# ESP32-S2 register map
Vendor: ESPRESSIF SYSTEMS (SHANGHAI) CO., LTD.; Series: ESP32 S-Series; File version: 20
CPU: Xtensa LX7 r0p0, little endian, no MPU, no FPU, 0 interrupt priority bits
Address unit: 32 bits
Registers are 32-bit, read-write, reset 0x0 unless marked. A register's access mark holds for its fields unless they carry their own. Offsets are from the block's base; [hi:lo] are bit positions; {n}, {i} and the like mark numbered series.

## UHCI0 — Universal Host Controller Interface 0
Base 0x3F414000
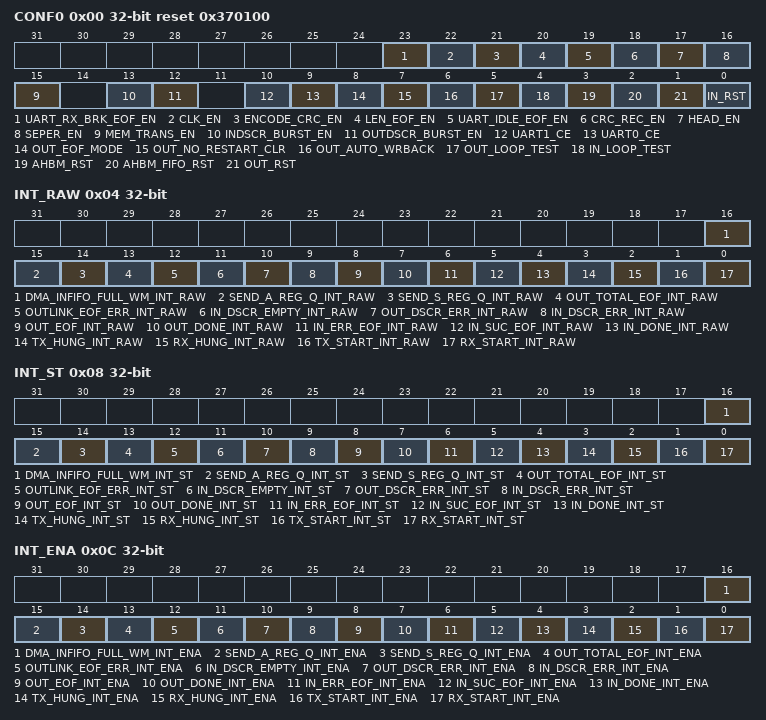
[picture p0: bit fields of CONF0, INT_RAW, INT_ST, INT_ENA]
0x00 CONF0 reset 0x370100 — UHCI configuration register
  [23] UART_RX_BRK_EOF_EN — If this bit is set to 1, UHCI stops receiving payload data when a NULL frame is received by UART.
  [22] CLK_EN — 1: Force clock on for registers. 0: Support clock only when application writes registers.
  [21] ENCODE_CRC_EN — Set this bit to enable data integrity checking by appending a 16 bit CCITT-CRC to the end of the payload.
  [20] LEN_EOF_EN — If this bit is set to 1, UHCI decoder stops receiving payload data when the number of received data bytes has reached the specified value. The value is payload length indicated by UCHI packet header when UHCI_HEAD_EN is 1 or the value is a configuration value when UHCI_HEAD_EN is 0. If this bit is set to 0, UHCI decoder stops receiving payload data upon receiving 0xC0.
  [19] UART_IDLE_EOF_EN — If this bit is set to 1, UHCI will end the payload receiving process when UART has been in idle state.
  [18] CRC_REC_EN — Set this bit to enable UHCI to receive the 16 bit CRC.
  [17] HEAD_EN — Set this bit to encode the data packet with a formatting header.
  [16] SEPER_EN — Set this bit to separate the data frame using a special character.
  [15] MEM_TRANS_EN — 1: UHCI transmitted data would be write back into DMA INFIFO.
  [13] INDSCR_BURST_EN — This register is used to specify DMA receive descriptor transfer mode. 1: burst mode. 0: byte mode.
  [12] OUTDSCR_BURST_EN — This register is used to specify DMA transmit descriptor transfer mode. 1: burst mode. 0: byte mode.
  [10] UART1_CE — Set this bit to link up UHCI and UART1.
  [9] UART0_CE — Set this bit to link up UHCI and UART0.
  [8] OUT_EOF_MODE — This register is used to specify the generation mode of UHCI_OUT_EOF_INT interrupt. 1: When DMA has popped all data from FIFO. 0: When AHB has pushed all data to FIFO.
  [7] OUT_NO_RESTART_CLR — Reserved.
  [6] OUT_AUTO_WRBACK — Set this bit to enable automatic outlink writeback when all the data in TX FIFO has been transmitted.
  [5] OUT_LOOP_TEST — Reserved.
  [4] IN_LOOP_TEST — Reserved.
  [3] AHBM_RST — Set this bit to reset AHB interface of DMA.
  [2] AHBM_FIFO_RST — Set this bit to reset AHB interface cmdFIFO of DMA.
  [1] OUT_RST — Set this bit to reset out DMA FSM.
  [0] IN_RST — Set this bit to reset in DMA FSM.
0x04 INT_RAW ro — Raw interrupt status
  [16] DMA_INFIFO_FULL_WM_INT_RAW — This is the interrupt raw bit for UHCI_DMA_INFIFO_FULL_WM_INT interrupt. The interrupt is triggered when the number of data bytes in DMA RX FIFO has reached the configured threshold value.
  [15] SEND_A_REG_Q_INT_RAW — This is the interrupt raw bit for UHCI_SEND_A_REG_Q_INT interrupt. The interrupt is triggered when DMA has sent out a short packet using always_send mode.
  [14] SEND_S_REG_Q_INT_RAW — This is the interrupt raw bit for UHCI_SEND_S_REG_Q_INT interrupt. The interrupt is triggered when DMA has sent out a short packet using single_send mode.
  [13] OUT_TOTAL_EOF_INT_RAW — This is the interrupt raw bit for UHCI_OUT_TOTAL_EOF_INT interrupt. The interrupt is triggered when all data in the last buffer address has been sent out.
  [12] OUTLINK_EOF_ERR_INT_RAW — This is the interrupt raw bit for UHCI_OUTLINK_EOF_ERR_INT interrupt. The interrupt is triggered when there are some errors in EOF in the transmit descriptor.
  [11] IN_DSCR_EMPTY_INT_RAW — This is the interrupt raw bit for UHCI_IN_DSCR_EMPTY_INT interrupt. The interrupt is triggered when there are not enough inlinks for DMA.
  [10] OUT_DSCR_ERR_INT_RAW — This is the interrupt raw bit for UHCI_OUT_DSCR_ERR_INT interrupt. The interrupt is triggered when there are some errors in the transmit descriptor.
  [9] IN_DSCR_ERR_INT_RAW — This is the interrupt raw bit for UHCI_IN_DSCR_ERR_INT interrupt. The interrupt is triggered when there are some errors in the receive descriptor.
  [8] OUT_EOF_INT_RAW — This is the interrupt raw bit for UHCI_OUT_EOF_INT interrupt. The interrupt is triggered when the current descriptor's EOF bit is 1.
  [7] OUT_DONE_INT_RAW — This is the interrupt raw bit for UHCI_OUT_DONE_INT interrupt. The interrupt is triggered when an transmit descriptor is completed.
  [6] IN_ERR_EOF_INT_RAW — This is the interrupt raw bit for UHCI_IN_ERR_EOF_INT interrupt. The interrupt is triggered when there are some errors in EOF in the receive descriptor.
  [5] IN_SUC_EOF_INT_RAW — This is the interrupt raw bit for UHCI_IN_SUC_EOF_INT interrupt. The interrupt is triggered when a data packet has been received successfully.
  [4] IN_DONE_INT_RAW — This is the interrupt raw bit for UHCI_IN_DONE_INT interrupt. The interrupt is triggered when an receive descriptor is completed.
  [3] TX_HUNG_INT_RAW — This is the interrupt raw bit for UHCI_TX_HUNG_INT interrupt. The interrupt is triggered when DMA takes more time to read data from RAM than the configured value.
  [2] RX_HUNG_INT_RAW — This is the interrupt raw bit for UHCI_RX_HUNG_INT interrupt. The interrupt is triggered when DMA takes more time to receive data than the configure value.
  [1] TX_START_INT_RAW — This is the interrupt raw bit for UHCI_TX_START_INT interrupt. The interrupt is triggered when DMA detects a separator.
  [0] RX_START_INT_RAW — This is the interrupt raw bit for UHCI_RX_START_INT interrupt. The interrupt is triggered when a separator has been sent.
0x08 INT_ST ro — Masked interrupt status
  [16] DMA_INFIFO_FULL_WM_INT_ST — This is the masked interrupt bit for UHCI_DMA_INFIFO_FULL_WM_INT INTERRUPT when UHCI_DMA_INFIFO_FULL_WM_INT_ENA is set to 1.
  [15] SEND_A_REG_Q_INT_ST — This is the masked interrupt bit for UHCI_SEND_A_REG_Q_INT interrupt when UHCI_SEND_A_REG_Q_INT_ENA is set to 1.
  [14] SEND_S_REG_Q_INT_ST — This is the masked interrupt bit for UHCI_SEND_S_REG_Q_INT interrupt when UHCI_SEND_S_REG_Q_INT_ENA is set to 1.
  [13] OUT_TOTAL_EOF_INT_ST — This is the masked interrupt bit for UHCI_OUT_TOTAL_EOF_INT interrupt when UHCI_OUT_TOTAL_EOF_INT_ENA is set to 1.
  [12] OUTLINK_EOF_ERR_INT_ST — This is the masked interrupt bit for UHCI_OUTLINK_EOF_ERR_INT interrupt when UHCI_OUTLINK_EOF_ERR_INT_ENA is set to 1.
  [11] IN_DSCR_EMPTY_INT_ST — This is the masked interrupt bit for UHCI_IN_DSCR_EMPTY_INT interrupt when UHCI_IN_DSCR_EMPTY_INT_ENA is set to 1.
  [10] OUT_DSCR_ERR_INT_ST — This is the masked interrupt bit for UHCI_OUT_DSCR_ERR_INT interrupt when UHCI_OUT_DSCR_ERR_INT_ENA is set to 1.
  [9] IN_DSCR_ERR_INT_ST — This is the masked interrupt bit for UHCI_IN_DSCR_ERR_INT interrupt when UHCI_IN_DSCR_ERR_INT is set to 1.
  [8] OUT_EOF_INT_ST — This is the masked interrupt bit for UHCI_OUT_EOF_INT interrupt when UHCI_OUT_EOF_INT_ENA is set to 1.
  [7] OUT_DONE_INT_ST — This is the masked interrupt bit for UHCI_OUT_DONE_INT interrupt when UHCI_OUT_DONE_INT_ENA is set to 1.
  [6] IN_ERR_EOF_INT_ST — This is the masked interrupt bit for UHCI_IN_ERR_EOF_INT interrupt when UHCI_IN_ERR_EOF_INT_ENA is set to 1.
  [5] IN_SUC_EOF_INT_ST — This is the masked interrupt bit for UHCI_IN_SUC_EOF_INT interrupt when UHCI_IN_SUC_EOF_INT_ENA is set to 1.
  [4] IN_DONE_INT_ST — This is the masked interrupt bit for UHCI_IN_DONE_INT interrupt when UHCI_IN_DONE_INT_ENA is set to 1.
  [3] TX_HUNG_INT_ST — This is the masked interrupt bit for UHCI_TX_HUNG_INT interrupt when UHCI_TX_HUNG_INT_ENA is set to 1.
  [2] RX_HUNG_INT_ST — This is the masked interrupt bit for UHCI_RX_HUNG_INT interrupt when UHCI_RX_HUNG_INT_ENA is set to 1.
  [1] TX_START_INT_ST — This is the masked interrupt bit for UHCI_TX_START_INT interrupt when UHCI_TX_START_INT_ENA is set to 1.
  [0] RX_START_INT_ST — This is the masked interrupt bit for UHCI_RX_START_INT interrupt when UHCI_RX_START_INT_ENA is set to 1.
0x0C INT_ENA — Interrupt enable bits
  [16] DMA_INFIFO_FULL_WM_INT_ENA — This is the interrupt enable bit for UHCI_DMA_INFIFO_FULL_WM_INT interrupt.
  [15] SEND_A_REG_Q_INT_ENA — This is the interrupt enable bit for UHCI_SEND_A_REG_Q_INT interrupt.
  [14] SEND_S_REG_Q_INT_ENA — This is the interrupt enable bit for UHCI_SEND_S_REG_Q_INT interrupt.
  [13] OUT_TOTAL_EOF_INT_ENA — This is the interrupt enable bit for UHCI_OUT_TOTAL_EOF_INT interrupt.
  [12] OUTLINK_EOF_ERR_INT_ENA — This is the interrupt enable bit for UHCI_OUTLINK_EOF_ERR_INT interrupt.
  [11] IN_DSCR_EMPTY_INT_ENA — This is the interrupt enable bit for UHCI_IN_DSCR_EMPTY_INT interrupt.
  [10] OUT_DSCR_ERR_INT_ENA — This is the interrupt enable bit for UHCI_OUT_DSCR_ERR_INT interrupt.
  [9] IN_DSCR_ERR_INT_ENA — This is the interrupt enable bit for UHCI_IN_DSCR_ERR_INT interrupt.
  [8] OUT_EOF_INT_ENA — This is the interrupt enable bit for UHCI_OUT_EOF_INT interrupt.
  [7] OUT_DONE_INT_ENA — This is the interrupt enable bit for UHCI_OUT_DONE_INT interrupt.
  [6] IN_ERR_EOF_INT_ENA — This is the interrupt enable bit for UHCI_IN_ERR_EOF_INT interrupt.
  [5] IN_SUC_EOF_INT_ENA — This is the interrupt enable bit for UHCI_IN_SUC_EOF_INT interrupt.
  [4] IN_DONE_INT_ENA — This is the interrupt enable bit for UHCI_IN_DONE_INT interrupt.
  [3] TX_HUNG_INT_ENA — This is the interrupt enable bit for UHCI_TX_HUNG_INT interrupt.
  [2] RX_HUNG_INT_ENA — This is the interrupt enable bit for UHCI_RX_HUNG_INT interrupt.
  [1] TX_START_INT_ENA — This is the interrupt enable bit for UHCI_TX_START_INT interrupt.
  [0] RX_START_INT_ENA — This is the interrupt enable bit for UHCI_RX_START_INT interrupt.
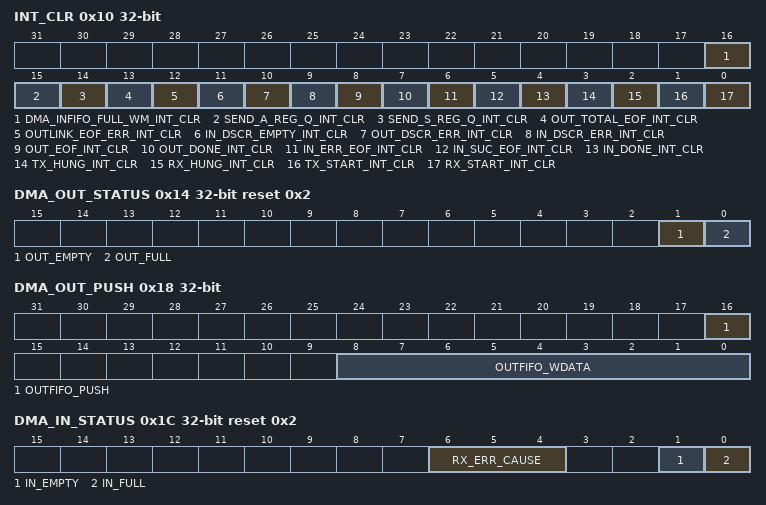
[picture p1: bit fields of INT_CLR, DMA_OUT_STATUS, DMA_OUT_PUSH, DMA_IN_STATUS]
0x10 INT_CLR wo — Interrupt clear bits
  [16] DMA_INFIFO_FULL_WM_INT_CLR — Set this bit to clear UHCI_DMA_INFIFO_FULL_WM_INT interrupt.
  [15] SEND_A_REG_Q_INT_CLR — Set this bit to clear UHCI_SEND_A_REG_Q_INT interrupt.
  [14] SEND_S_REG_Q_INT_CLR — Set this bit to clear UHCI_SEND_S_REG_Q_INT interrupt.
  [13] OUT_TOTAL_EOF_INT_CLR — Set this bit to clear UHCI_OUT_TOTAL_EOF_INT interrupt.
  [12] OUTLINK_EOF_ERR_INT_CLR — Set this bit to clear UHCI_OUTLINK_EOF_ERR_INT interrupt.
  [11] IN_DSCR_EMPTY_INT_CLR — Set this bit to clear UHCI_IN_DSCR_EMPTY_INT interrupt.
  [10] OUT_DSCR_ERR_INT_CLR — Set this bit to clear UHCI_OUT_DSCR_ERR_INT interrupt.
  [9] IN_DSCR_ERR_INT_CLR — Set this bit to clear UHCI_IN_DSCR_ERR_INT interrupt.
  [8] OUT_EOF_INT_CLR — Set this bit to clear UHCI_OUT_EOF_INT interrupt.
  [7] OUT_DONE_INT_CLR — Set this bit to clear UHCI_OUT_DONE_INT interrupt.
  [6] IN_ERR_EOF_INT_CLR — Set this bit to clear UHCI_IN_ERR_EOF_INT interrupt.
  [5] IN_SUC_EOF_INT_CLR — Set this bit to clear UHCI_IN_SUC_EOF_INT interrupt.
  [4] IN_DONE_INT_CLR — Set this bit to clear UHCI_IN_DONE_INT interrupt.
  [3] TX_HUNG_INT_CLR — Set this bit to clear UHCI_TX_HUNG_INT interrupt.
  [2] RX_HUNG_INT_CLR — Set this bit to clear UHCI_RX_HUNG_INT interrupt.
  [1] TX_START_INT_CLR — Set this bit to clear UHCI_TX_START_INT interrupt.
  [0] RX_START_INT_CLR — Set this bit to clear UHCI_RX_START_INT interrupt.
0x14 DMA_OUT_STATUS ro reset 0x2 — DMA data-output status register
  [1] OUT_EMPTY — 1: DMA TX FIFO is empty.
  [0] OUT_FULL — 1: DMA TX FIFO is full.
0x18 DMA_OUT_PUSH — Push control register of TX FIFO
  [16] OUTFIFO_PUSH — Set this bit to push data into TX FIFO.
  [8:0] OUTFIFO_WDATA — This is the data that need to be pushed into TX FIFO.
0x1C DMA_IN_STATUS ro reset 0x2 — UHCI data-input status register
  [6:4] RX_ERR_CAUSE — This register indicates the error type when DMA has received a packet with error. 3'b001: Checksum error in the HCI packet; 3'b010: Sequence number error in the HCI packet; 3'b011: CRC bit error in the HCI packet; 3'b100: 0xC0 is found but the received HCI packet is not end; 3'b101: 0xC0 is not found when the HCI packet has been received; 3'b110: CRC check error.
  [1] IN_EMPTY — Data-input FIFO empty signal.
  [0] IN_FULL — Data-input FIFO full signal.
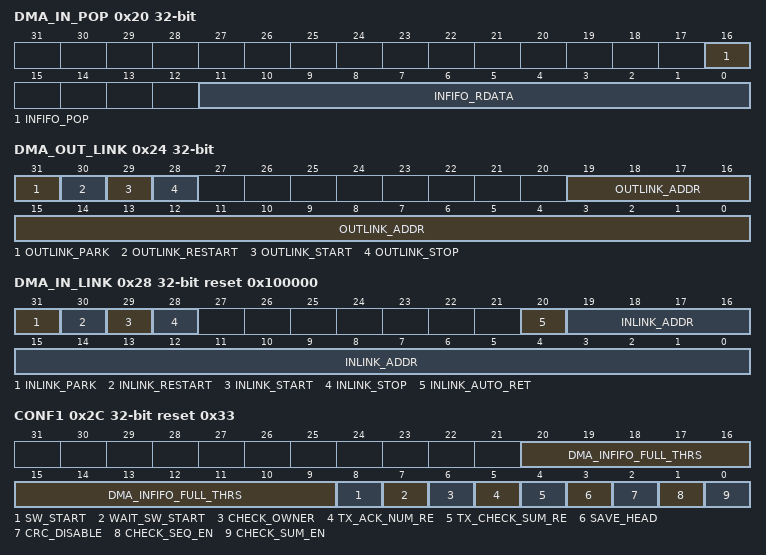
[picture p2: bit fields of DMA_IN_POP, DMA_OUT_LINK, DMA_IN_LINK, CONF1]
0x20 DMA_IN_POP access per field — Pop control register of RX FIFO
  [16] INFIFO_POP rw — Set this bit to pop data from RX FIFO.
  [11:0] INFIFO_RDATA ro — This register stores the data popping from RX FIFO.
0x24 DMA_OUT_LINK access per field — Link descriptor address and control
  [31] OUTLINK_PARK ro — 1: the transmit descriptor's FSM is in idle state. 0: the transmit descriptor's FSM is working.
  [30] OUTLINK_RESTART rw — Set this bit to restart the transmit descriptor from the last address.
  [29] OUTLINK_START rw — Set this bit to start a new transmit descriptor.
  [28] OUTLINK_STOP rw — Set this bit to stop dealing with the transmit descriptor.
  [19:0] OUTLINK_ADDR rw — This register is used to specify the least significant 20 bits of the first transmit descriptor's address.
0x28 DMA_IN_LINK access per field reset 0x100000 — Link descriptor address and control
  [31] INLINK_PARK ro — 1: the receive descriptor's FSM is in idle state. 0: the receive descriptor's FSM is working.
  [30] INLINK_RESTART rw — Set this bit to restart new receive descriptors.
  [29] INLINK_START rw — Set this bit to start dealing with the receive descriptors.
  [28] INLINK_STOP rw — Set this bit to stop dealing with the receive descriptors.
  [20] INLINK_AUTO_RET rw — This is the enable bit to return to current receive descriptor's address, when there are some errors in current packet.
  [19:0] INLINK_ADDR rw — This register is used to specify the least significant 20 bits of the first receive descriptor's address.
0x2C CONF1 reset 0x33 — UHCI configuration register
  [20:9] DMA_INFIFO_FULL_THRS — This field is used to generate the UHCI_DMA_INFIFO_FULL_WM_INT interrupt when the counter value of DMA RX FIFO exceeds the value of the register.
  [8] SW_START — If current UHCI_ENCODE_STATE is ST_SW_WAIT, the UHCI will start to send data packet out when this bit is set to 1.
  [7] WAIT_SW_START — The UHCI encoder will jump to ST_SW_WAIT status if this register is set to 1.
  [6] CHECK_OWNER — 1: Check the link list descriptor when link list owner is DMA controller; 0: Always check link list descriptor.
  [5] TX_ACK_NUM_RE — Set this bit to encode the data packet with an acknowledgement when a reliable packet is to be transmit.
  [4] TX_CHECK_SUM_RE — Set this bit to encode the data packet with a checksum.
  [3] SAVE_HEAD — Set this bit to save the packet header when UHCI receives a data packet.
  [2] CRC_DISABLE — Set this bit to support CRC calculation. Data Integrity check present bit in UHCI packet frame should be 1.
  [1] CHECK_SEQ_EN — This is the enable bit to check sequence number when UHCI receives a data packet.
  [0] CHECK_SUM_EN — This is the enable bit to check header checksum when UHCI receives a data packet.
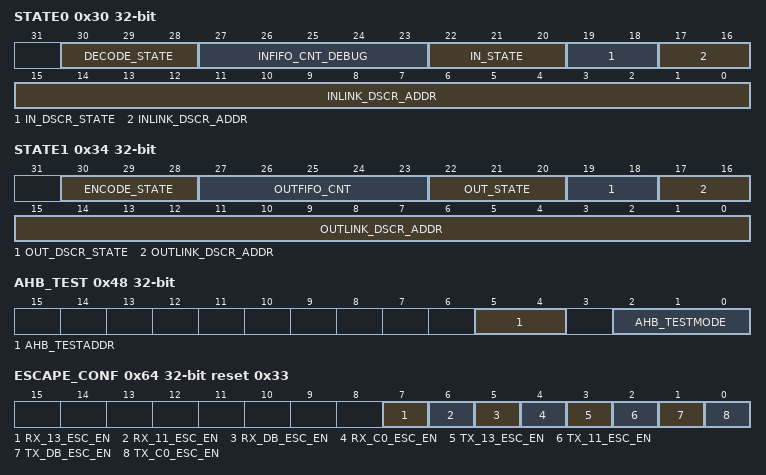
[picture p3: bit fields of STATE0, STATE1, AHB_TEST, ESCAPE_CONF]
0x30 STATE0 ro — UHCI decoder status register
  [30:28] DECODE_STATE — UHCI decoder status.
  [27:23] INFIFO_CNT_DEBUG — This register stores the number of data bytes in RX FIFO.
  [22:20] IN_STATE — Reserved.
  [19:18] IN_DSCR_STATE — Reserved.
  [17:0] INLINK_DSCR_ADDR — This register stores the current receive descriptor's address.
0x34 STATE1 ro — UHCI encoder status register
  [30:28] ENCODE_STATE — UHCI encoder status.
  [27:23] OUTFIFO_CNT — This register stores the number of data bytes in TX FIFO.
  [22:20] OUT_STATE — Reserved.
  [19:18] OUT_DSCR_STATE — Reserved.
  [17:0] OUTLINK_DSCR_ADDR — This register stores the current transmit descriptor's address.
0x38 DMA_OUT_EOF_DES_ADDR ro — Outlink descriptor address when EOF occurs
  [31:0] OUT_EOF_DES_ADDR — This register stores the address of the transmit descriptor when the EOF bit in this descriptor is 1.
0x3C DMA_IN_SUC_EOF_DES_ADDR ro — Inlink descriptor address when EOF occurs
  [31:0] IN_SUC_EOF_DES_ADDR — This register stores the address of the receive descriptor when received successful EOF.
0x40 DMA_IN_ERR_EOF_DES_ADDR ro — Inlink descriptor address when errors occur
  [31:0] IN_ERR_EOF_DES_ADDR — This register stores the address of the receive descriptor when there are some errors in this descriptor.
0x44 DMA_OUT_EOF_BFR_DES_ADDR ro — Outlink descriptor address before the last transmit descriptor
  [31:0] OUT_EOF_BFR_DES_ADDR — This register stores the address of the transmit descriptor before the last transmit descriptor.
0x48 AHB_TEST
  [5:4] AHB_TESTADDR — Reserved.
  [2:0] AHB_TESTMODE — Reserved.
0x4C DMA_IN_DSCR ro — The third word of the next receive descriptor
  [31:0] INLINK_DSCR — This register stores the third word of the next receive descriptor.
0x50 DMA_IN_DSCR_BF0 ro — The third word of current receive descriptor
  [31:0] INLINK_DSCR_BF0 — This register stores the third word of the current receive descriptor.
0x58 DMA_OUT_DSCR ro — The third word of the next transmit descriptor
  [31:0] OUTLINK_DSCR — This register stores the third word of the next transmit descriptor.
0x5C DMA_OUT_DSCR_BF0 ro — The third word of current transmit descriptor
  [31:0] OUTLINK_DSCR_BF0 — This register stores the third word of the current transmit descriptor.
0x64 ESCAPE_CONF reset 0x33 — Escape character configuration
  [7] RX_13_ESC_EN — Set this bit to replace flow control character 0x13 by special characters when DMA sends data.
  [6] RX_11_ESC_EN — Set this bit to replace flow control character 0x11 by special characters when DMA sends data.
  [5] RX_DB_ESC_EN — Set this bit to replace 0xDB by special characters when DMA sends data.
  [4] RX_C0_ESC_EN — Set this bit to replace 0xC0 by special characters when DMA sends data.
  [3] TX_13_ESC_EN — Set this bit to decode flow control character 0x13 when DMA receives data.
  [2] TX_11_ESC_EN — Set this bit to decode flow control character 0x11 when DMA receives data.
  [1] TX_DB_ESC_EN — Set this bit to decode character 0xDB when DMA receives data.
  [0] TX_C0_ESC_EN — Set this bit to decode character 0xC0 when DMA receives data.
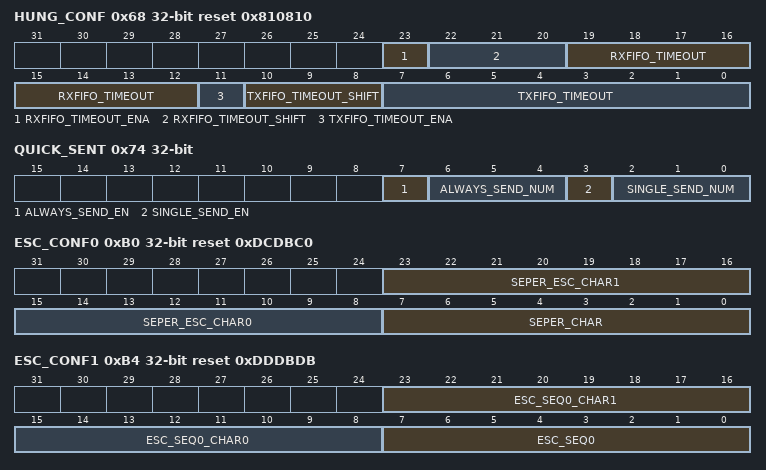
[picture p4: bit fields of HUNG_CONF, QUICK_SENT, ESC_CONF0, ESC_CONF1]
0x68 HUNG_CONF reset 0x810810 — Timeout configuration
  [23] RXFIFO_TIMEOUT_ENA — This is the enable bit for DMA send timeout.
  [22:20] RXFIFO_TIMEOUT_SHIFT — This register is used to configure the maximum tick count.
  [19:12] RXFIFO_TIMEOUT — This register stores the timeout value. UHCI produce the UHCI_RX_HUNG_INT interrupt when DMA takes more time to read data from RAM.
  [11] TXFIFO_TIMEOUT_ENA — This is the enable bit for TX FIFO receive timeout.
  [10:8] TXFIFO_TIMEOUT_SHIFT — This register is used to configure the maximum tick count.
  [7:0] TXFIFO_TIMEOUT — This register stores the timeout value. UHCI produce the UHCI_TX_HUNG_INT interrupt when DMA takes more time to receive data.
0x70 RX_HEAD ro — UHCI packet header register
  [31:0] RX_HEAD — This register stores the header of the current received packet.
0x74 QUICK_SENT — UHCI quick_sent configuration register
  [7] ALWAYS_SEND_EN — Set this bit to enable always_send mode to send short packets.
  [6:4] ALWAYS_SEND_NUM — This register is used to specify the always_send mode.
  [3] SINGLE_SEND_EN — Set this bit to enable single_send mode to send short packets.
  [2:0] SINGLE_SEND_NUM — This register is used to specify the single_send mode.
{0x78+8i} Q{i}_WORD0 (i=0..6) — Q{i}_WORD0 quick_sent register
  [31:0] SEND_Q{i}_WORD0 — This register is used as a quick_sent register when mode is specified by UHCI_ALWAYS_SEND_NUM or UHCI_SINGLE_SEND_NUM.
{0x7C+8i} Q{i}_WORD1 (i=0..6) — Q{i}_WORD1 quick_sent register
  [31:0] SEND_Q{i}_WORD1 — This register is used as a quick_sent register when mode is specified by UHCI_ALWAYS_SEND_NUM or UHCI_SINGLE_SEND_NUM.
0xB0 ESC_CONF0 reset 0xDCDBC0 — Escape sequence configuration register 0
  [23:16] SEPER_ESC_CHAR1 — This register is used to define the second character of SLIP escape sequence. The default value is 0xDC.
  [15:8] SEPER_ESC_CHAR0 — This register is used to define the first character of SLIP escape sequence. The default value is 0xDB.
  [7:0] SEPER_CHAR — This register is used to define separators to encode data packets. The default value is 0xC0.
0xB4 ESC_CONF1 reset 0xDDDBDB — Escape sequence configuration register 1
  [23:16] ESC_SEQ0_CHAR1 — This register is used to define the second character of SLIP escape sequence. The default value is 0xDD.
  [15:8] ESC_SEQ0_CHAR0 — This register is used to define the first character of SLIP escape sequence. The default value is 0xDB.
  [7:0] ESC_SEQ0 — This register is used to define a character that need to be encoded. The default value is 0xDB that used as the first character of SLIP escape sequence.
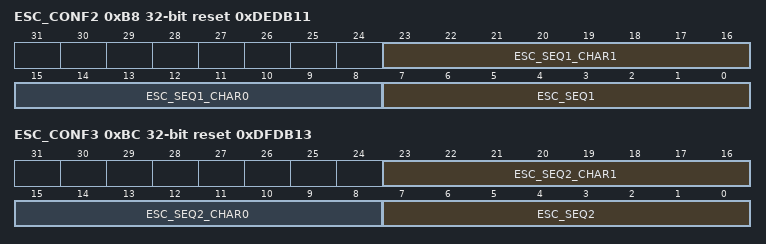
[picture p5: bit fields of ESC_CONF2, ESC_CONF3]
0xB8 ESC_CONF2 reset 0xDEDB11 — Escape sequence configuration register 2
  [23:16] ESC_SEQ1_CHAR1 — This register is used to define the second character of SLIP escape sequence. The default value is 0xDE.
  [15:8] ESC_SEQ1_CHAR0 — This register is used to define the first character of SLIP escape sequence. The default value is 0xDB.
  [7:0] ESC_SEQ1 — This register is used to define a character that need to be encoded. The default value is 0x11 that used as a flow control character.
0xBC ESC_CONF3 reset 0xDFDB13 — Escape sequence configuration register 3
  [23:16] ESC_SEQ2_CHAR1 — This register is used to define the second character of SLIP escape sequence. The default value is 0xDF.
  [15:8] ESC_SEQ2_CHAR0 — This register is used to define the first character of SLIP escape sequence. The default value is 0xDB.
  [7:0] ESC_SEQ2 — This register is used to define a character that need to be decoded. The default value is 0x13 that used as a flow control character.
0xC0 PKT_THRES reset 0x80 — Configure register for packet length
  [12:0] PKT_THRS — This register is used to configure the maximum value of the packet length when UHCI_HEAD_EN is 0.
0xFC DATE reset 0x18073001 — UHCI version control register
  [31:0] DATE — This is the version control register.
